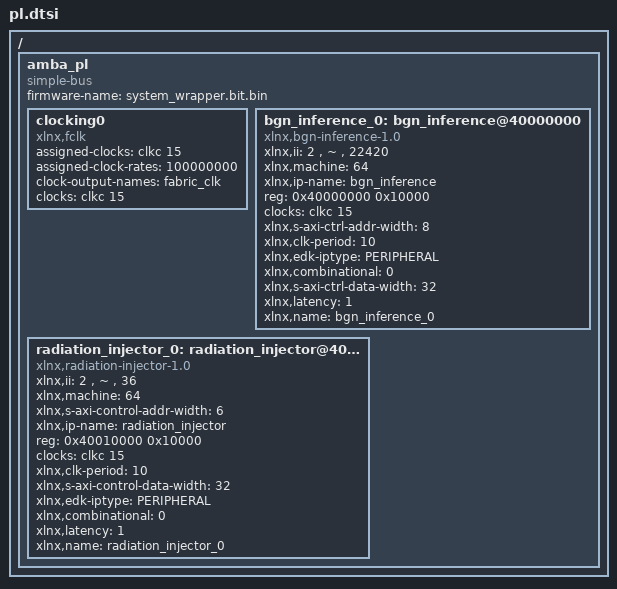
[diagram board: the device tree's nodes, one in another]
/ {
	amba_pl: amba_pl {
		ranges;
		compatible = "simple-bus";
		#address-cells = <1>;
		#size-cells = <1>;
		firmware-name = "system_wrapper.bit.bin";
		clocking0: clocking0 {
			compatible = "xlnx,fclk";
			assigned-clocks = <&clkc 15>;
			assigned-clock-rates = <100000000>;
			#clock-cells = <0>;
			clock-output-names = "fabric_clk";
			clocks = <&clkc 15>;
		};
		bgn_inference_0: bgn_inference@40000000 {
			compatible = "xlnx,bgn-inference-1.0";
			xlnx,ii = "2 , ~ , 22420";
			xlnx,machine = <64>;
			xlnx,ip-name = "bgn_inference";
			reg = <0x40000000 0x10000>;
			clocks = <&clkc 15>;
			xlnx,s-axi-ctrl-addr-width = <8>;
			xlnx,clk-period = <10>;
			xlnx,edk-iptype = "PERIPHERAL";
			status = "okay";
			clock-names = "ap_clk";
			xlnx,combinational = <0>;
			xlnx,s-axi-ctrl-data-width = <32>;
			xlnx,latency = <1>;
			xlnx,name = "bgn_inference_0";
		};
		radiation_injector_0: radiation_injector@40010000 {
			compatible = "xlnx,radiation-injector-1.0";
			xlnx,ii = "2 , ~ , 36";
			xlnx,machine = <64>;
			xlnx,s-axi-control-addr-width = <6>;
			xlnx,ip-name = "radiation_injector";
			reg = <0x40010000 0x10000>;
			clocks = <&clkc 15>;
			xlnx,clk-period = <10>;
			xlnx,s-axi-control-data-width = <32>;
			xlnx,edk-iptype = "PERIPHERAL";
			status = "okay";
			clock-names = "ap_clk";
			xlnx,combinational = <0>;
			xlnx,latency = <1>;
			xlnx,name = "radiation_injector_0";
		};
	};
};
